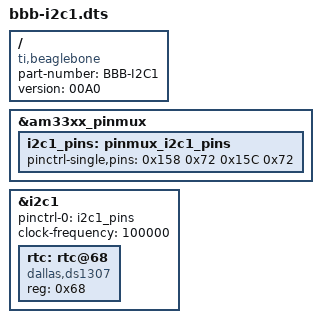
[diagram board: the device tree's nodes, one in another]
// Custom device tree overlay to enable i2c1 with suitable pin configuration

/dts-v1/;
/plugin/;

/{
	compatible = "ti,beaglebone", "ti,beaglebone-black";
	part-number = "BBB-I2C1";
	version = "00A0";

	fragment@0 {
		target = <&am33xx_pinmux>;

		__overlay__ {
			i2c1_pins: pinmux_i2c1_pins {
				pinctrl-single,pins = <
					0x158 0x72 /* spi0_d1.i2c1_sda */
					0x15C 0x72 /* spi0_cs0.i2c1_sdl */
				>;
			};
		};
	};

	fragment@1 {
		target = <&i2c1>;

		__overlay__ {
			#address-cells = <0x1>;
			#size-cells = <0x0>;
			pinctrl-names ="default";
			pinctrl-0 = <&i2c1_pins>;

			status = "okay";
			clock-frequency = <100000>;

			rtc: rtc@68 {
				#address-cells = <1>;
				#size-cells = <0>;
				compatible = "dallas,ds1307";
				reg = <0x68>;
			};
		};
	};
};
